AUTOSAR XML (schema 4-2-2)
package /STELLANTIS/EPT/ASWCs
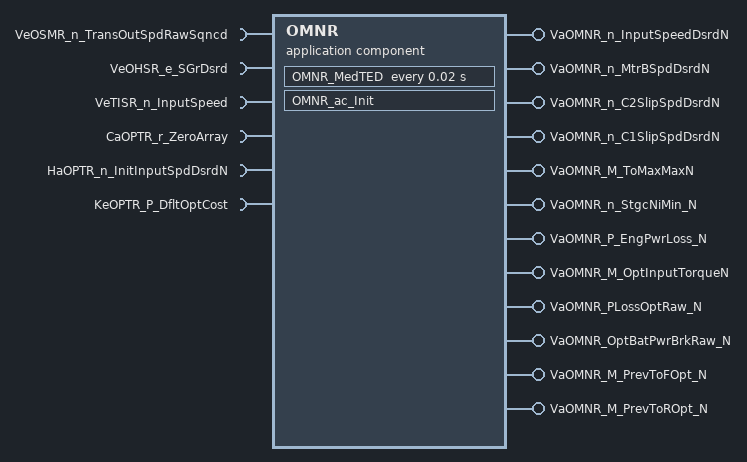
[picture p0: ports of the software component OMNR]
  application sw component type OMNR
    require port VeOSMR_n_TransOutSpdRawSqncd: nonqueued-receiver-com-spec{data-element=Value, init-value=0}, required-interface=VeOSMR_n_TransOutSpdRawSqncd
    require port VeOHSR_e_SGrDsrd: nonqueued-receiver-com-spec{data-element=Value, init-value=CeOHSR_e_SG_Reverse}, required-interface=VeOHSR_e_SGrDsrd
    require port VeTISR_n_InputSpeed: nonqueued-receiver-com-spec{data-element=Value, init-value=0}, required-interface=VeTISR_n_InputSpeed
    12 x provide port, all with nonqueued-sender-com-spec{data-element=Value, init-value=9 x 0}:
      VaOMNR_n_InputSpeedDsrdN: provided-interface=VaOMNR_n_InputSpeedDsrdN
      VaOMNR_n_MtrBSpdDsrdN: provided-interface=VaOMNR_n_MtrBSpdDsrdN
      VaOMNR_n_C2SlipSpdDsrdN: provided-interface=VaOMNR_n_C2SlipSpdDsrdN
      VaOMNR_n_C1SlipSpdDsrdN: provided-interface=VaOMNR_n_C1SlipSpdDsrdN
      VaOMNR_M_ToMaxMaxN: provided-interface=VaOMNR_M_ToMaxMaxN
      VaOMNR_n_StgcNiMin_N: provided-interface=VaOMNR_n_StgcNiMin_N
      VaOMNR_P_EngPwrLoss_N: provided-interface=VaOMNR_P_EngPwrLoss_N
      VaOMNR_M_OptInputTorqueN: provided-interface=VaOMNR_M_OptInputTorqueN
      VaOMNR_PLossOptRaw_N: provided-interface=VaOMNR_PLossOptRaw_N
      VaOMNR_OptBatPwrBrkRaw_N: provided-interface=VaOMNR_OptBatPwrBrkRaw_N
      VaOMNR_M_PrevToFOpt_N: provided-interface=VaOMNR_M_PrevToFOpt_N
      VaOMNR_M_PrevToROpt_N: provided-interface=VaOMNR_M_PrevToROpt_N
    require port CaOPTR_r_ZeroArray: parameter-require-com-spec{init-value=CaOPTR_r_ZeroArray_CaOPTR_r_ZeroArray:[CaOPTR_r_ZeroArray_CaOPTR_r_ZeroArray_rt_Array_Float_9_1:0, CaOPTR_r_ZeroArray_CaOPTR_r_ZeroArray_rt_Array_Float_9_2:0, CaOPTR_r_ZeroArray_CaOPTR_r_ZeroArray_rt_Array_Float_9_3:0, CaOPTR_r_ZeroArray_CaOPTR_r_ZeroArray_rt_Array_Float_9_4:0, CaOPTR_r_ZeroArray_CaOPTR_r_ZeroArray_rt_Array_Float_9_5:0, CaOPTR_r_ZeroArray_CaOPTR_r_ZeroArray_rt_Array_Float_9_6:0, CaOPTR_r_ZeroArray_CaOPTR_r_ZeroArray_rt_Array_Float_9_7:0, CaOPTR_r_ZeroArray_CaOPTR_r_ZeroArray_rt_Array_Float_9_8:0, CaOPTR_r_ZeroArray_CaOPTR_r_ZeroArray_rt_Array_Float_9_9:0], parameter=CaOPTR_r_ZeroArray}, required-interface=CaOPTR_r_ZeroArray
    require port HaOPTR_n_InitInputSpdDsrdN: parameter-require-com-spec{init-value=9 x 500, parameter=HaOPTR_n_InitInputSpdDsrdN}, required-interface=HaOPTR_n_InitInputSpdDsrdN
    require port KeOPTR_P_DfltOptCost: parameter-require-com-spec{init-value=KeOPTR_P_DfltOptCost_KeOPTR_P_DfltOptCost:1000000, parameter=KeOPTR_P_DfltOptCost}, required-interface=KeOPTR_P_DfltOptCost
    behavior IB_OMNR: data-type-mapping=msADTtoIDTMapping, handle-termination-and-restart=NO-SUPPORT, included-data-type-set=data-type=TeTSXR_e_PrfrdComb
      timing event Event_MedTED: start-on-event=OMNR_MedTED, period=0.02
      init event Event_OMNR_ac_Init: start-on-event=OMNR_ac_Init
      runnable OMNR_ac_Init
        data-send-points:
          12 x access:
            OUT_VaOMNR_n_StgcNiMin_N_Value: accessed-variable=VaOMNR_n_StgcNiMin_N.Value
            OUT_VaOMNR_n_C1SlipSpdDsrdN_Value: accessed-variable=VaOMNR_n_C1SlipSpdDsrdN.Value
            OUT_VaOMNR_n_C2SlipSpdDsrdN_Value: accessed-variable=VaOMNR_n_C2SlipSpdDsrdN.Value
            OUT_VaOMNR_n_InputSpeedDsrdN_Value: accessed-variable=VaOMNR_n_InputSpeedDsrdN.Value
            OUT_VaOMNR_n_MtrBSpdDsrdN_Value: accessed-variable=VaOMNR_n_MtrBSpdDsrdN.Value
            OUT_VaOMNR_PLossOptRaw_N_Value: accessed-variable=VaOMNR_PLossOptRaw_N.Value
            OUT_VaOMNR_P_EngPwrLoss_N_Value: accessed-variable=VaOMNR_P_EngPwrLoss_N.Value
            OUT_VaOMNR_M_ToMaxMaxN_Value: accessed-variable=VaOMNR_M_ToMaxMaxN.Value
            OUT_VaOMNR_M_OptInputTorqueN_Value: accessed-variable=VaOMNR_M_OptInputTorqueN.Value
            OUT_VaOMNR_OptBatPwrBrkRaw_N_Value: accessed-variable=VaOMNR_OptBatPwrBrkRaw_N.Value
            OUT_VaOMNR_M_PrevToFOpt_N_Value: accessed-variable=VaOMNR_M_PrevToFOpt_N.Value
            OUT_VaOMNR_M_PrevToROpt_N_Value: accessed-variable=VaOMNR_M_PrevToROpt_N.Value
        parameter access CALPRM_CaOPTR_r_ZeroArray_CaOPTR_r_ZeroArray: accessed-parameter=CaOPTR_r_ZeroArray.CaOPTR_r_ZeroArray
        parameter access CALPRM_HaOPTR_n_InitInputSpdDsrdN_HaOPTR_n_InitInputSpdDsrdN: accessed-parameter=HaOPTR_n_InitInputSpdDsrdN.HaOPTR_n_InitInputSpdDsrdN
        parameter access CALPRM_KeOPTR_P_DfltOptCost_KeOPTR_P_DfltOptCost: accessed-parameter=KeOPTR_P_DfltOptCost.KeOPTR_P_DfltOptCost
      runnable OMNR_MedTED
        data-receive-point-by-arguments:
          access IN_VeTISR_n_InputSpeed_Value: accessed-variable=VeTISR_n_InputSpeed.Value
        data-send-points:
          12 x access:
            OUT_VaOMNR_n_InputSpeedDsrdN_Value: accessed-variable=VaOMNR_n_InputSpeedDsrdN.Value
            OUT_VaOMNR_n_MtrBSpdDsrdN_Value: accessed-variable=VaOMNR_n_MtrBSpdDsrdN.Value
            OUT_VaOMNR_n_C1SlipSpdDsrdN_Value: accessed-variable=VaOMNR_n_C1SlipSpdDsrdN.Value
            OUT_VaOMNR_n_C2SlipSpdDsrdN_Value: accessed-variable=VaOMNR_n_C2SlipSpdDsrdN.Value
            OUT_VaOMNR_M_ToMaxMaxN_Value: accessed-variable=VaOMNR_M_ToMaxMaxN.Value
            OUT_VaOMNR_n_StgcNiMin_N_Value: accessed-variable=VaOMNR_n_StgcNiMin_N.Value
            OUT_VaOMNR_P_EngPwrLoss_N_Value: accessed-variable=VaOMNR_P_EngPwrLoss_N.Value
            OUT_VaOMNR_M_OptInputTorqueN_Value: accessed-variable=VaOMNR_M_OptInputTorqueN.Value
            OUT_VaOMNR_PLossOptRaw_N_Value: accessed-variable=VaOMNR_PLossOptRaw_N.Value
            OUT_VaOMNR_OptBatPwrBrkRaw_N_Value: accessed-variable=VaOMNR_OptBatPwrBrkRaw_N.Value
            OUT_VaOMNR_M_PrevToFOpt_N_Value: accessed-variable=VaOMNR_M_PrevToFOpt_N.Value
            OUT_VaOMNR_M_PrevToROpt_N_Value: accessed-variable=VaOMNR_M_PrevToROpt_N.Value
        parameter access CALPRM_CaOPTR_r_ZeroArray_CaOPTR_r_ZeroArray: accessed-parameter=CaOPTR_r_ZeroArray.CaOPTR_r_ZeroArray
        parameter access CALPRM_KeOPTR_P_DfltOptCost_KeOPTR_P_DfltOptCost: accessed-parameter=KeOPTR_P_DfltOptCost.KeOPTR_P_DfltOptCost
      15 x variation point proxy, all with category=CONDITION:
        Variant_HSCL_3Mot_Enbl: condition-access=0
        Variant_OMNR_EnblN: condition-access=0
        Variant_OPTR_Enbl3MtrSys: condition-access=0
        Variant_OPTR_EnblPwrPnlCnstr: condition-access=0
        Variant_OPTR_EnblTCCCalc: condition-access=0
        Variant_OPTR_EnblWEDRsrv: condition-access=1
        Variant_OPTR_HiResSrchNiPiLims: condition-access=0
        Variant_OPTR_OptBatPwrBrkEnbl: condition-access=1
        Variant_OPTR_ZrPdlToMinAtTeMin: condition-access=0
        Variant_TSXR_MtrALimToFSel: condition-access=1
        Variant_TSXR_MtrALimToRSel: condition-access=0
        Variant_TSXR_MtrBLimToFSel: condition-access=0
        Variant_TSXR_MtrBLimToRSel: condition-access=1
        Variant_TSXR_MtrCLimToFSel: condition-access=0
        Variant_TSXR_MtrCLimToRSel: condition-access=0
